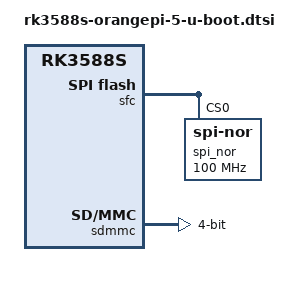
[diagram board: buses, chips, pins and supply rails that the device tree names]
// SPDX-License-Identifier: (GPL-2.0+ OR MIT)

#include "rk3588s-u-boot.dtsi"

/ {
	aliases {
		mmc0 = &sdhci;
		mmc1 = &sdmmc;
	};

	chosen {
		u-boot,spl-boot-order = &sdmmc, &sdhci, &spi_nor;
	};
};

&fspim0_pins {
	bootph-all;
};

&sfc {
	bootph-pre-ram;
	u-boot,spl-sfc-no-dma;
	pinctrl-names = "default";
	pinctrl-0 = <&fspim0_pins>;
	#address-cells = <1>;
	#size-cells = <0>;
	status = "okay";

	spi_nor: flash@0 {
		bootph-pre-ram;
		compatible = "jedec,spi-nor";
		reg = <0>;
		spi-max-frequency = <100000000>;
		spi-rx-bus-width = <4>;
		spi-tx-bus-width = <1>;
	};
};

&sdmmc {
	bus-width = <4>;
	status = "okay";
};

&sdhci {
	cap-mmc-highspeed;
	mmc-ddr-1_8v;
	mmc-hs200-1_8v;
    status = "disabled";
};
